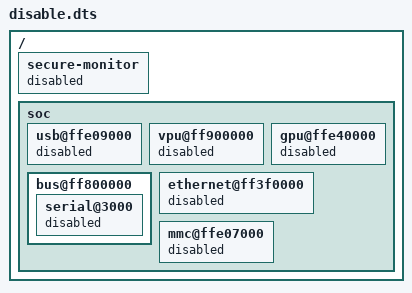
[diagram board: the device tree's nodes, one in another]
/*
 * Copyright 2024, UNSW
 *
 * SPDX-License-Identifier: BSD-2-Clause
 */
/ {
    secure-monitor {
		status = "disabled";
	};

    soc {
        usb@ffe09000 {
            status = "disabled";
        };

        vpu@ff900000 {
            status = "disabled";
        };

        gpu@ffe40000 {
            status = "disabled";
        };

        bus@ff800000 {
            // enable/disable console serial for debugging 
            serial@3000 {
                status = "disabled";
            };
        };

        ethernet@ff3f0000 {
            status = "disabled";
        };

        mmc@ffe07000 {
            status = "disabled";
        };
    };
};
